# SPC1068 register map
File version: 20180100_70611510
CPU: CM3 r2p1, little endian, MPU, no FPU, 4 interrupt priority bits
Registers are 32-bit, read-write, reset 0x0 unless marked. A register's access mark holds for its fields unless they carry their own. Offsets are from the block's base; [hi:lo] are bit positions; 'fields as' and 'values as' point back to an identical list.

## COMP — Split from ADC
Base 0x4000A000
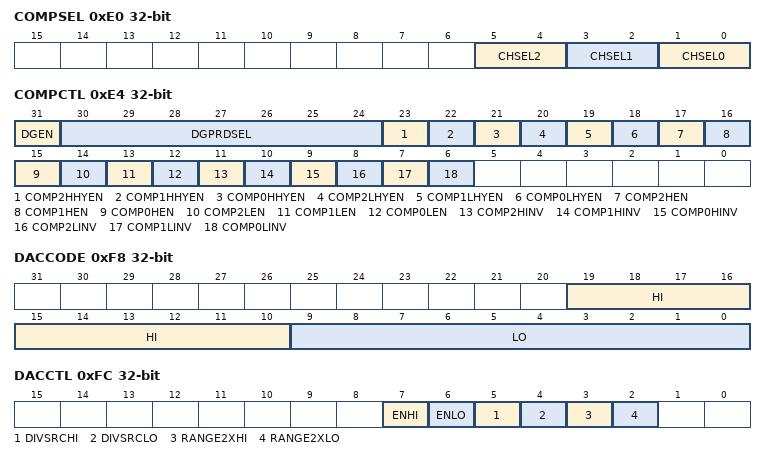
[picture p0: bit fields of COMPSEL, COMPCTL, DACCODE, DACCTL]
0xE0 COMPSEL — Comparator Input Selection Register
  [5:4] CHSEL2 — Select the input source of high speed comparator in PGA 2
    0=PGA2N_OUT (Select the input source of high speed comparator as output of pga2n); 1=PGA2P_OUT (Select the input source of high speed comparator as output of pga2p); 2=PGA2N_IN (Select the input source of high speed comparator as input of pga2n); 3=PGA2P_IN (Select the input source of high speed comparator as input of pga2p)
  [3:2] CHSEL1 — Select the input source of high speed comparator in PGA 1
    0=PGA1N_OUT (Select the input source of high speed comparator as output of pga1n); 1=PGA1P_OUT (Select the input source of high speed comparator as output of pga1p); 2=PGA1N_IN (Select the input source of high speed comparator as input of pga1n); 3=PGA1P_IN (Select the input source of high speed comparator as input of pga1p)
  [1:0] CHSEL0 — Select the input source of high speed comparator in PGA 0
    0=PGA0N_OUT (Select the input source of high speed comparator as output of pga0n); 1=PGA0P_OUT (Select the input source of high speed comparator as output of pga0p); 2=PGA0N_IN (Select the input source of high speed comparator as input of pga0n); 3=PGA0P_IN (Select the input source of high speed comparator as input of pga0p)
0xE4 COMPCTL — Comparator Control Register
  [31] DGEN — Synchronization select for output of the comparator before being passed to PWM/GPIO blocks
    0=FILTER_DISABLE (Asynchronous version of Comparator output is passed); 1=FILTER_ENABLE (Synchronous version of comparator output is passed)
  [30:24] DGPRDSEL — Qualification period for synchronized output of the comparator. 00h: Synchronized value of comparator is passed through. 01h: Input to the block must be consistent for 2 consecutive clocks before output of deglitch block can change. 02h: Input to the block must be consistent for 3 consecutive clocks before output of deglitch block can change ...... 7fh: Input to the block must be consistent for 128 consecutive clocks before output of deglitch block can change
  [23] COMP2HHYEN — Enable high speed comparator's hysteresis of high-voltage protection in PGA 2
    0=DISABLE (Disable hysteresis); 1=ENABLE (Enable hysteresis)
  [22] COMP1HHYEN — Enable high speed comparator's hysteresis of high-voltage protection in PGA 1
    0=DISABLE (Disable hysteresis); 1=ENABLE (Enable hysteresis)
  [21] COMP0HHYEN — Enable high speed comparator's hysteresis of high-voltage protection in PGA 0
    0=DISABLE (Disable hysteresis); 1=ENABLE (Enable hysteresis)
  [20] COMP2LHYEN — Enable high speed comparator's hysteresis of low-voltage protection in PGA 2
    0=DISABLE (Disable hysteresis); 1=ENABLE (Enable hysteresis)
  [19] COMP1LHYEN — Enable high speed comparator's hysteresis of low-voltage protection in PGA 1
    0=DISABLE (Disable hysteresis); 1=ENABLE (Enable hysteresis)
  [18] COMP0LHYEN — Enable high speed comparator's hysteresis of low-voltage protection in PGA 0
    0=DISABLE (Disable hysteresis); 1=ENABLE (Enable hysteresis)
  [17] COMP2HEN — Enable the high speed comparator of high-voltage protection in PGA2
    0=DISABLE (Disable Comparator); 1=ENABLE (Enable Comparator)
  [16] COMP1HEN — Enable the high speed comparator of high-voltage protection in PGA1
    0=DISABLE (Disable Comparator); 1=ENABLE (Enable Comparator)
  [15] COMP0HEN — Enable the high speed comparator of high-voltage protection in PGA0
    0=DISABLE (Disable Comparator); 1=ENABLE (Enable Comparator)
  [14] COMP2LEN — Enable the high speed comparator of low-voltage protection in PGA2
    0=DISABLE (Disable Comparator); 1=ENABLE (Enable Comparator)
  [13] COMP1LEN — Enable the high speed comparator of low-voltage protection in PGA1
    0=DISABLE (Disable Comparator); 1=ENABLE (Enable Comparator)
  [12] COMP0LEN — Enable the high speed comparator of low-voltage protection in PGA0
    0=DISABLE (Disable Comparator); 1=ENABLE (Enable Comparator)
  [11] COMP2HINV — Invert the output of high speed comparator for high-voltage protection in PGA 2
    0=DISABLE (Keep the output of high speed comparator); 1=ENABLE (Invert the output of high speed comparator)
  [10] COMP1HINV — Invert the output of high speed comparator for high-voltage protection in PGA 1
    values as COMP2HINV
  [9] COMP0HINV — Invert the output of high speed comparator for high-voltage protection in PGA 0
    values as COMP2HINV
  [8] COMP2LINV — Invert the output of high speed comparator for low-voltage protection in PGA 2
    values as COMP2HINV
  [7] COMP1LINV — Invert the output of high speed comparator for low-voltage protection in PGA 1
    values as COMP2HINV
  [6] COMP0LINV — Invert the output of high speed comparator for low-voltage protection in PGA 0
    values as COMP2HINV
0xF8 DACCODE
  [19:10] HI — Digital input of 10-bit DAC for high-ref
  [9:0] LO — Digital input of 10-bit DAC for low-ref
0xFC DACCTL — DAC Control Register
  [7] ENHI — Enable 10-bit DAC to send HIGH ref for comparator
    0=DISABLE (Disable DAC High); 1=ENABLE (Enable DAC High)
  [6] ENLO — Enable 10-bit DAC to send LOW ref for comparator
    0=DISABLE (Disable DAC Low); 1=ENABLE (Enable DAC Low)
  [5] DIVSRCHI — Select DAC High DAC Driving Mode
    0=CURRENT_DRV (Enable current driving mode as High DAC output, 10 bit resolution); 1=VDDX_DRV (Enable VDDX divider mode as High DAC output, MSB 7 bit resolution)
  [4] DIVSRCLO — Select DAC Low DAC Driving Mode
    values as DIVSRCHI
  [3] RANGE2XHI — Select High DAC range in current driving mode
    0=0_TO_1dot1_V (Set output range for high ref DAC to be 0~1.1V in current driving mode); 1=0_TO_2dot2_V (Set output range for high ref DAC to be 0~2.2V in current driving mode)
  [2] RANGE2XLO — Select Low DAC range in current driving mode
    0=0_TO_1dot1_V (Set output range for low ref DAC to be 0~1.1V in current driving mode); 1=0_TO_2dot2_V (Set output range for low ref DAC to be 0~2.2V in current driving mode)
